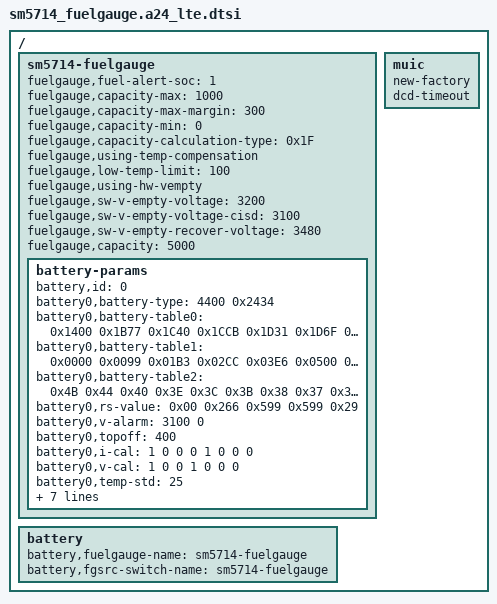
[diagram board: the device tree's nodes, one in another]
// SPDX-License-Identifier: (GPL-2.0 OR MIT)
/*
 * Copyright (C) 2022 MediaTek Inc.
 */

/ {
	fragment@smd {
		target-path = "/";
		__overlay__ {
			sm5714-fuelgauge {
				status = "okay";
				fuelgauge,fuel-alert-soc = <1>;
				fuelgauge,capacity-max = <1000>;
				fuelgauge,capacity-max-margin = <300>;
				fuelgauge,capacity-min = <0>;
				fuelgauge,capacity-calculation-type = <0x1F>;
				fuelgauge,using-temp-compensation;
				fuelgauge,low-temp-limit = <100>;
				fuelgauge,using-hw-vempty;
				fuelgauge,sw-v-empty-voltage = <3200>;
				fuelgauge,sw-v-empty-voltage-cisd = <3100>;
				fuelgauge,sw-v-empty-recover-voltage = <3480>;
				fuelgauge,capacity = <5000>;
				battery-params {
					battery,id = <0>;
					battery0,battery-type = <4400 0x2434>; /* batt_v_max, cap */
					battery0,battery-table0 = <
						0x1400 0x1B77 0x1C40 0x1CCB 0x1D31 0x1D6F 0x1D81 0x1D88
						0x1DA0 0x1DE3 0x1E1F 0x1E45 0x1E5E 0x1E7E 0x1EA7 0x1EDC
						0x1EFE 0x1F7C 0x1FCC 0x2054 0x20BB 0x2144 0x223E 0x2400
						>;
					battery0,battery-table1 = <
						0x0000 0x0099 0x01B3 0x02CC 0x03E6 0x0500 0x07B3 0x0A80
						0x0D4C 0x12CC 0x1B19 0x2099 0x2619 0x2B99 0x3133 0x36B3
						0x3980 0x3F00 0x4480 0x4CCC 0x524C 0x58E6 0x6400 0x6419
						>;
					battery0,battery-table2 = <
						0x4B 0x44 0x40 0x3E 0x3C 0x3B 0x38 0x37
						0x35 0x34 0x34 0x33 0x33 0x33 0x33 0x32
						>;
					/* spare factor chg_factor dischg_factor manvalue */
					battery0,rs-value = <0x00 0x266 0x599 0x599 0x29>;
					battery0,v-alarm = <3100 0>;
					battery0,topoff = <400>;
					battery0,i-cal = <1 0 0 0 1 0 0 0 >;
					battery0,v-cal = <1 0 0 1 0 0 0>;
					battery0,temp-std = <25>;
					battery0,tem-poff = <3400 50 3250 50>;
					battery0,aux-ctrl = <0x303>;
					battery0,data-ver = <1>;
					battery0,v-max-table = <0x223E 0x221C 0x21FA 0x21D9 0x2184>;
					battery0,q-max-table = <0x2434 0x23A8 0x231D 0x2291 0x2134>;
				};
			};

			battery {
				battery,fuelgauge-name = "sm5714-fuelgauge";
				battery,fgsrc-switch-name = "sm5714-fuelgauge";
			};

			muic {
				new-factory;
				dcd-timeout;
			};
		};
	};
};
